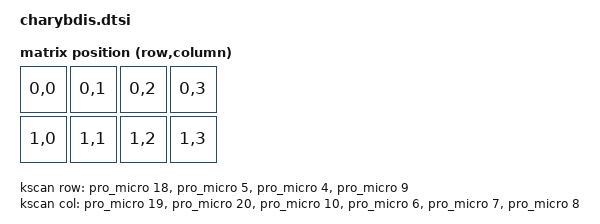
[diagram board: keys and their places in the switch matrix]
// This file was generated from a template. Edit it to match your keyboard.
// See https://zmk.dev/docs/development/hardware-integration/new-shield for more
// instructions.

#include <dt-bindings/zmk/matrix_transform.h>

#include "charybdis-layouts.dtsi"

/ {
    chosen {
        zmk,physical-layout = &default_layout;
    };

    kscan: kscan {
        compatible = "zmk,kscan-gpio-matrix";
        diode-direction = "col2row";
        wakeup-source;

        col-gpios
            = <&pro_micro 19 (GPIO_ACTIVE_HIGH | GPIO_PULL_DOWN)>
            , <&pro_micro 20 (GPIO_ACTIVE_HIGH | GPIO_PULL_DOWN)>
            , <&pro_micro 10 (GPIO_ACTIVE_HIGH | GPIO_PULL_DOWN)>
            , <&pro_micro 6 (GPIO_ACTIVE_HIGH | GPIO_PULL_DOWN)>
            , <&pro_micro 7 (GPIO_ACTIVE_HIGH | GPIO_PULL_DOWN)>
            , <&pro_micro 8 (GPIO_ACTIVE_HIGH | GPIO_PULL_DOWN)>
            ;

        row-gpios
            = <&pro_micro 18 GPIO_ACTIVE_HIGH>
            , <&pro_micro 5 GPIO_ACTIVE_HIGH>
            , <&pro_micro 4 GPIO_ACTIVE_HIGH>
            , <&pro_micro 9 GPIO_ACTIVE_HIGH>
            ;
    };

    default_transform: default_transform {
        // See https://zmk.dev/docs/development/hardware-integration/new-shield#matrix-transform
        // for how to configure this
        compatible = "zmk,matrix-transform";
        columns = <4>;
        rows = <2>;

        map = <
            RC(0, 0) RC(0, 1)    RC(0, 2) RC(0, 3)
            RC(1, 0) RC(1, 1)    RC(1, 2) RC(1, 3)
        >;
    };
};
